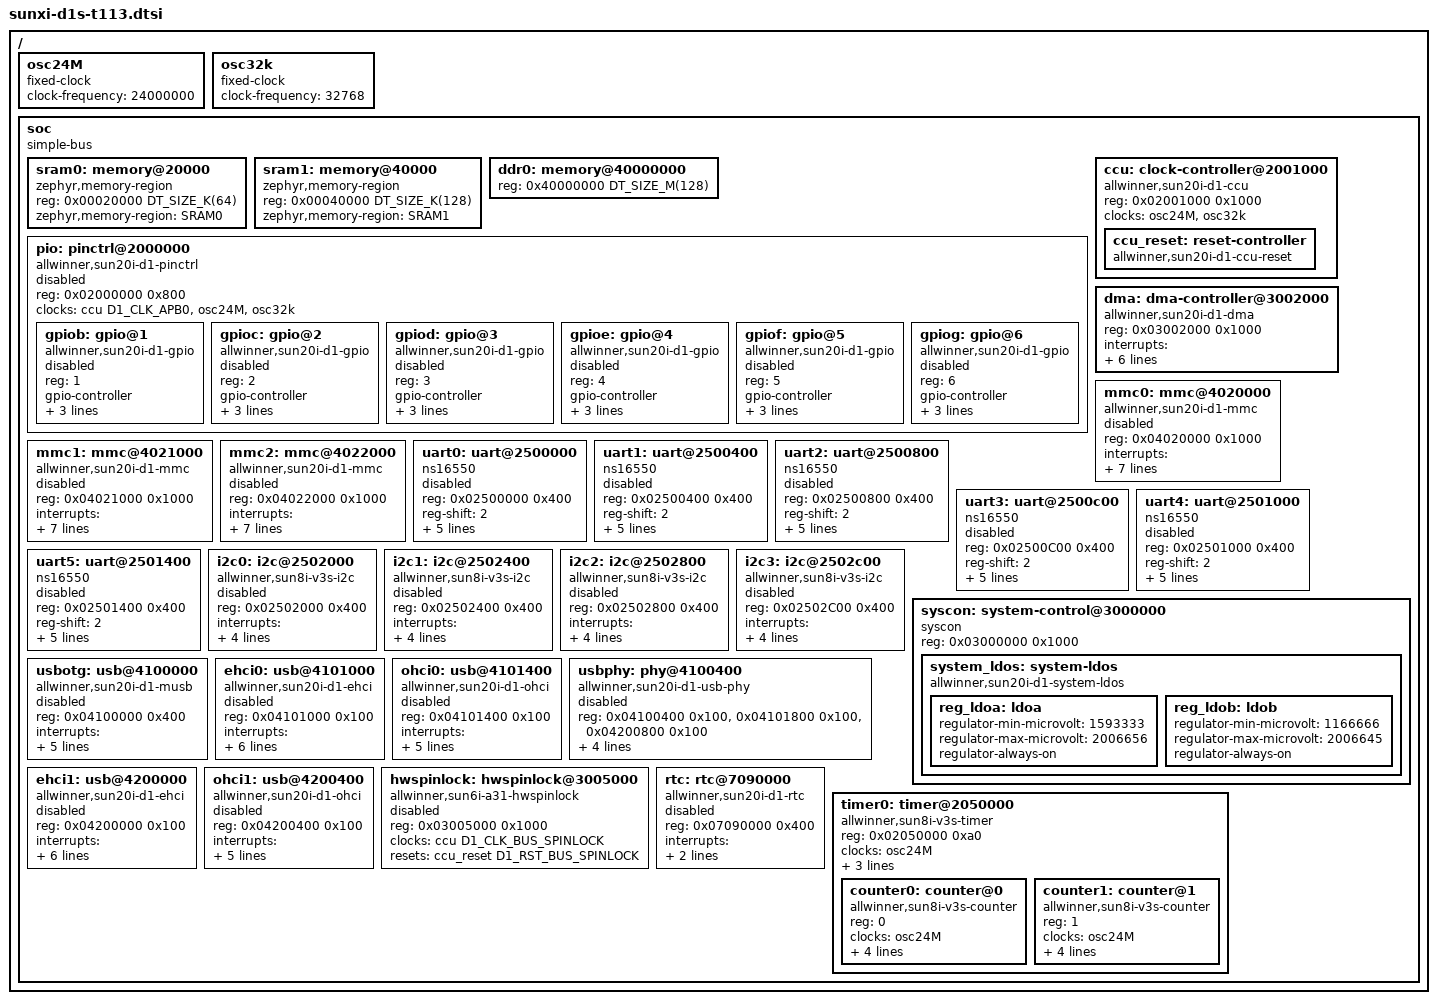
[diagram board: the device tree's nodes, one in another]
/*
 * Copyright (c) 2026 jeck chen <baidxi404629@gmail.com>
 * SPDX-License-Identifier: Apache-2.0
 *
 * Allwinner D1s / T113-S3 shared peripheral definitions.
 */

#include <mem.h>
#include <freq.h>
#include <zephyr/dt-bindings/interrupt-controller/arm-gic.h>
#include <zephyr/dt-bindings/clock/sun20i-d1-ccu.h>
#include <zephyr/dt-bindings/reset/sun20i-d1-ccu.h>
#include <zephyr/dt-bindings/dma/allwinner,sun20i-d1-dma.h>

/ {
	osc24M: osc24M {
		compatible = "fixed-clock";
		clock-frequency = <24000000>;
		#clock-cells = <0>;
	};

	osc32k: osc32k {
		compatible = "fixed-clock";
		clock-frequency = <32768>;
		#clock-cells = <0>;
	};

	soc {
		compatible = "simple-bus";
		#address-cells = <1>;
		#size-cells = <1>;
		ranges;

		sram0: memory@20000 {
			device_type = "memory";
			compatible = "zephyr,memory-region", "mmio-sram";
			reg = <0x00020000 DT_SIZE_K(64)>;
			zephyr,memory-region = "SRAM0";
		};

		sram1: memory@40000 {
			device_type = "memory";
			compatible = "zephyr,memory-region", "mmio-sram";
			reg = <0x00040000 DT_SIZE_K(128)>;
			zephyr,memory-region = "SRAM1";
		};

		ddr0: memory@40000000 {
			device_type = "memory";
			reg = <0x40000000 DT_SIZE_M(128)>;
		};

		pio: pinctrl@2000000 {
			compatible = "allwinner,sun20i-d1-pinctrl";
			reg = <0x02000000 0x800>;
			clocks = <&ccu D1_CLK_APB0>, <&osc24M>, <&osc32k>;
			clock-names = "apb", "hosc", "losc";
			#address-cells = <1>;
			#size-cells = <0>;
			status = "disabled";

			/*
			 * PLIC IRQ per bank (from Linux sunxi-d1s-t113.dtsi):
			 * PB=69, PC=71, PD=73, PE=75, PF=77, PG=79
			 */
			gpiob: gpio@1 {
				compatible = "allwinner,sun20i-d1-gpio";
				reg = <1>;
				gpio-controller;
				#gpio-cells = <2>;
				interrupt-parent = <&gic>;
				interrupts = <GIC_SPI 69 IRQ_TYPE_LEVEL IRQ_DEFAULT_PRIORITY>;
				status = "disabled";
			};
			gpioc: gpio@2 {
				compatible = "allwinner,sun20i-d1-gpio";
				reg = <2>;
				gpio-controller;
				#gpio-cells = <2>;
				interrupt-parent = <&gic>;
				interrupts = <GIC_SPI 71 IRQ_TYPE_LEVEL IRQ_DEFAULT_PRIORITY>;
				status = "disabled";
			};
			gpiod: gpio@3 {
				compatible = "allwinner,sun20i-d1-gpio";
				reg = <3>;
				gpio-controller;
				#gpio-cells = <2>;
				interrupt-parent = <&gic>;
				interrupts = <GIC_SPI 73 IRQ_TYPE_LEVEL IRQ_DEFAULT_PRIORITY>;
				status = "disabled";
			};
			gpioe: gpio@4 {
				compatible = "allwinner,sun20i-d1-gpio";
				reg = <4>;
				gpio-controller;
				#gpio-cells = <2>;
				interrupt-parent = <&gic>;
				interrupts = <GIC_SPI 75 IRQ_TYPE_LEVEL IRQ_DEFAULT_PRIORITY>;
				status = "disabled";
			};
			gpiof: gpio@5 {
				compatible = "allwinner,sun20i-d1-gpio";
				reg = <5>;
				gpio-controller;
				#gpio-cells = <2>;
				interrupt-parent = <&gic>;
				interrupts = <GIC_SPI 77 IRQ_TYPE_LEVEL IRQ_DEFAULT_PRIORITY>;
				status = "disabled";
			};
			gpiog: gpio@6 {
				compatible = "allwinner,sun20i-d1-gpio";
				reg = <6>;
				gpio-controller;
				#gpio-cells = <2>;
				interrupt-parent = <&gic>;
				interrupts = <GIC_SPI 79 IRQ_TYPE_LEVEL IRQ_DEFAULT_PRIORITY>;
				status = "disabled";
			};
		};

		ccu: clock-controller@2001000 {
			compatible = "allwinner,sun20i-d1-ccu";
			reg = <0x02001000 0x1000>;
			clocks = <&osc24M>, <&osc32k>;
			clock-names = "hosc", "losc";
			#clock-cells = <1>;
			#reset-cells = <1>;
			status = "okay";

			ccu_reset: reset-controller {
				compatible = "allwinner,sun20i-d1-ccu-reset";
				#reset-cells = <1>;
				status = "okay";
			};
		};

		dma: dma-controller@3002000 {
			compatible = "allwinner,sun20i-d1-dma";
			reg = <0x03002000 0x1000>;
			interrupts = <GIC_SPI 50 IRQ_TYPE_LEVEL IRQ_DEFAULT_PRIORITY>;
			clocks = <&ccu D1_CLK_BUS_DMA>, <&ccu D1_CLK_MBUS_DMA>;
			clock-names = "bus", "mbus";
			resets = <&ccu_reset D1_RST_BUS_DMA>;
			dma-channels = <16>;
			dma-requests = <48>;
			#dma-cells = <1>;
			status = "okay";
		};

		mmc0: mmc@4020000 {
			compatible = "allwinner,sun20i-d1-mmc";
			reg = <0x04020000 0x1000>;
			interrupts = <GIC_SPI 40 IRQ_TYPE_LEVEL IRQ_DEFAULT_PRIORITY>;
			clocks = <&ccu D1_CLK_BUS_MMC0>, <&ccu D1_CLK_MMC0>,
				 <&ccu D1_CLK_MMC0_OUTPUT>, <&ccu D1_CLK_MMC0_SAMPLE>;
			clock-names = "ahb", "mmc", "output", "sample";
			resets = <&ccu_reset D1_RST_BUS_MMC0>;
			reset-names = "ahb";
			bus-width = <4>;
			frequency = <DT_FREQ_M(24)>;
			status = "disabled";
			/* pinctrl provided by board overlay */
		};

		mmc1: mmc@4021000 {
			compatible = "allwinner,sun20i-d1-mmc";
			reg = <0x04021000 0x1000>;
			interrupts = <GIC_SPI 41 IRQ_TYPE_LEVEL IRQ_DEFAULT_PRIORITY>;
			clocks = <&ccu D1_CLK_BUS_MMC1>, <&ccu D1_CLK_MMC1>,
				 <&ccu D1_CLK_MMC1_OUTPUT>, <&ccu D1_CLK_MMC1_SAMPLE>;
			clock-names = "ahb", "mmc", "output", "sample";
			resets = <&ccu_reset D1_RST_BUS_MMC1>;
			reset-names = "ahb";
			bus-width = <4>;
			frequency = <DT_FREQ_M(24)>;
			status = "disabled";
			/* pinctrl provided by board overlay */
		};

		mmc2: mmc@4022000 {
			compatible = "allwinner,sun20i-d1-mmc";
			reg = <0x04022000 0x1000>;
			interrupts = <GIC_SPI 42 IRQ_TYPE_LEVEL IRQ_DEFAULT_PRIORITY>;
			clocks = <&ccu D1_CLK_BUS_MMC2>, <&ccu D1_CLK_MMC2>,
				 <&ccu D1_CLK_MMC2_OUTPUT>, <&ccu D1_CLK_MMC2_SAMPLE>;
			clock-names = "ahb", "mmc", "output", "sample";
			resets = <&ccu_reset D1_RST_BUS_MMC2>;
			reset-names = "ahb";
			bus-width = <8>;
			frequency = <DT_FREQ_M(24)>;
			status = "disabled";
			/* pinctrl provided by board overlay */
		};

		uart0: uart@2500000 {
			compatible = "ns16550", "snps,dw-apb-uart";
			reg = <0x02500000 0x400>;
			reg-shift = <2>;
			interrupts = <GIC_SPI 2 IRQ_TYPE_LEVEL IRQ_DEFAULT_PRIORITY>;
			clocks = <&ccu D1_CLK_BUS_UART0>;
			resets = <&ccu_reset D1_RST_BUS_UART0>;
			clock-frequency = <DT_FREQ_M(24)>;
			status = "disabled";
		};

		uart1: uart@2500400 {
			compatible = "ns16550", "snps,dw-apb-uart";
			reg = <0x02500400 0x400>;
			reg-shift = <2>;
			interrupts = <GIC_SPI 3 IRQ_TYPE_LEVEL IRQ_DEFAULT_PRIORITY>;
			clocks = <&ccu D1_CLK_BUS_UART1>;
			resets = <&ccu_reset D1_RST_BUS_UART1>;
			clock-frequency = <DT_FREQ_M(24)>;
			status = "disabled";
		};

		uart2: uart@2500800 {
			compatible = "ns16550", "snps,dw-apb-uart";
			reg = <0x02500800 0x400>;
			reg-shift = <2>;
			interrupts = <GIC_SPI 4 IRQ_TYPE_LEVEL IRQ_DEFAULT_PRIORITY>;
			clocks = <&ccu D1_CLK_BUS_UART2>;
			resets = <&ccu_reset D1_RST_BUS_UART2>;
			clock-frequency = <DT_FREQ_M(24)>;
			status = "disabled";
		};

		uart3: uart@2500c00 {
			compatible = "ns16550", "snps,dw-apb-uart";
			reg = <0x02500C00 0x400>;
			reg-shift = <2>;
			interrupts = <GIC_SPI 5 IRQ_TYPE_LEVEL IRQ_DEFAULT_PRIORITY>;
			clocks = <&ccu D1_CLK_BUS_UART3>;
			resets = <&ccu_reset D1_RST_BUS_UART3>;
			clock-frequency = <DT_FREQ_M(24)>;
			status = "disabled";
		};

		uart4: uart@2501000 {
			compatible = "ns16550", "snps,dw-apb-uart";
			reg = <0x02501000 0x400>;
			reg-shift = <2>;
			interrupts = <GIC_SPI 6 IRQ_TYPE_LEVEL IRQ_DEFAULT_PRIORITY>;
			clocks = <&ccu D1_CLK_BUS_UART4>;
			resets = <&ccu_reset D1_RST_BUS_UART4>;
			clock-frequency = <DT_FREQ_M(24)>;
			status = "disabled";
		};

		uart5: uart@2501400 {
			compatible = "ns16550", "snps,dw-apb-uart";
			reg = <0x02501400 0x400>;
			reg-shift = <2>;
			interrupts = <GIC_SPI 7 IRQ_TYPE_LEVEL IRQ_DEFAULT_PRIORITY>;
			clocks = <&ccu D1_CLK_BUS_UART5>;
			resets = <&ccu_reset D1_RST_BUS_UART5>;
			clock-frequency = <DT_FREQ_M(24)>;
			status = "disabled";
		};

		i2c0: i2c@2502000 {
			compatible = "allwinner,sun8i-v3s-i2c",
				     "allwinner,sun20i-d1-i2c";
			reg = <0x02502000 0x400>;
			interrupts = <GIC_SPI 9 IRQ_TYPE_LEVEL IRQ_DEFAULT_PRIORITY>;
			clocks = <&ccu D1_CLK_BUS_I2C0>;
			clock-names = "bus";
			resets = <&ccu_reset D1_RST_BUS_I2C0>;
			clock-frequency = <100000>;
			#address-cells = <1>;
			#size-cells = <0>;
			status = "disabled";
		};

		i2c1: i2c@2502400 {
			compatible = "allwinner,sun8i-v3s-i2c",
				     "allwinner,sun20i-d1-i2c";
			reg = <0x02502400 0x400>;
			interrupts = <GIC_SPI 10 IRQ_TYPE_LEVEL IRQ_DEFAULT_PRIORITY>;
			clocks = <&ccu D1_CLK_BUS_I2C1>;
			clock-names = "bus";
			resets = <&ccu_reset D1_RST_BUS_I2C1>;
			clock-frequency = <100000>;
			#address-cells = <1>;
			#size-cells = <0>;
			status = "disabled";
		};

		i2c2: i2c@2502800 {
			compatible = "allwinner,sun8i-v3s-i2c",
				     "allwinner,sun20i-d1-i2c";
			reg = <0x02502800 0x400>;
			interrupts = <GIC_SPI 11 IRQ_TYPE_LEVEL IRQ_DEFAULT_PRIORITY>;
			clocks = <&ccu D1_CLK_BUS_I2C2>;
			clock-names = "bus";
			resets = <&ccu_reset D1_RST_BUS_I2C2>;
			clock-frequency = <100000>;
			#address-cells = <1>;
			#size-cells = <0>;
			status = "disabled";
		};

		i2c3: i2c@2502c00 {
			compatible = "allwinner,sun8i-v3s-i2c",
				     "allwinner,sun20i-d1-i2c";
			reg = <0x02502C00 0x400>;
			interrupts = <GIC_SPI 12 IRQ_TYPE_LEVEL IRQ_DEFAULT_PRIORITY>;
			clocks = <&ccu D1_CLK_BUS_I2C3>;
			clock-names = "bus";
			resets = <&ccu_reset D1_RST_BUS_I2C3>;
			clock-frequency = <100000>;
			#address-cells = <1>;
			#size-cells = <0>;
			status = "disabled";
		};

		/* System Configuration (SYS_CFG) — base 0x03000000.
		 * Contains EMAC EPHY clock register (0x30), system LDOs
		 * (0x150), and DSP SRAM remap (0x08).
		 */
		syscon: system-control@3000000 {
			compatible = "syscon";
			reg = <0x03000000 0x1000>;
			status = "okay";

			system_ldos: system-ldos {
				compatible = "allwinner,sun20i-d1-system-ldos";
				status = "okay";

				reg_ldoa: ldoa {
					/* 1.593V – 2.007V, 32 steps (13.33mV/step) */
					regulator-min-microvolt = <1593333>;
					regulator-max-microvolt = <2006656>;
					regulator-always-on;
				};

				reg_ldob: ldob {
					/* 1.167V – 2.007V, 64 steps (13.33mV/step) */
					regulator-min-microvolt = <1166666>;
					regulator-max-microvolt = <2006645>;
					regulator-always-on;
				};
			};
		};

		usbotg: usb@4100000 {
			compatible = "allwinner,sun20i-d1-musb",
				     "allwinner,sun8i-v3s-musb";
			reg = <0x04100000 0x400>;
			interrupts = <GIC_SPI 29 IRQ_TYPE_LEVEL IRQ_DEFAULT_PRIORITY>;
			clocks = <&ccu D1_CLK_BUS_OTG>;
			resets = <&ccu_reset D1_RST_BUS_OTG>;
			phys = <&usbphy 0>;
			phy-names = "usb";
			num-bidir-endpoints = <6>;
			status = "disabled";
		};

		ehci0: usb@4101000 {
			compatible = "allwinner,sun20i-d1-ehci", "generic-ehci";
			reg = <0x04101000 0x100>;
			interrupts = <GIC_SPI 30 IRQ_TYPE_LEVEL IRQ_DEFAULT_PRIORITY>;
			clocks = <&ccu D1_CLK_BUS_OHCI0>,
				 <&ccu D1_CLK_BUS_EHCI0>,
				 <&ccu D1_CLK_USB_OHCI0>;
			resets = <&ccu_reset D1_RST_BUS_OHCI0>,
				 <&ccu_reset D1_RST_BUS_EHCI0>;
			phys = <&usbphy 0>;
			phy-names = "usb";
			status = "disabled";
		};

		ohci0: usb@4101400 {
			compatible = "allwinner,sun20i-d1-ohci", "generic-ohci";
			reg = <0x04101400 0x100>;
			interrupts = <GIC_SPI 31 IRQ_TYPE_LEVEL IRQ_DEFAULT_PRIORITY>;
			clocks = <&ccu D1_CLK_BUS_OHCI0>,
				 <&ccu D1_CLK_USB_OHCI0>;
			resets = <&ccu_reset D1_RST_BUS_OHCI0>;
			phys = <&usbphy 0>;
			phy-names = "usb";
			status = "disabled";
		};

		usbphy: phy@4100400 {
			compatible = "allwinner,sun20i-d1-usb-phy",
				     "allwinner,sun4i-usb-phy";
			reg = <0x04100400 0x100>,
			      <0x04101800 0x100>,
			      <0x04200800 0x100>;
			reg-names = "phy_ctrl", "pmu0", "pmu1";
			clocks = <&osc24M>,
				 <&osc24M>;
			clock-names = "usb0_phy", "usb1_phy";
			resets = <&ccu_reset D1_RST_USB_PHY0>,
				 <&ccu_reset D1_RST_USB_PHY1>;
			reset-names = "usb0_reset", "usb1_reset";
			#phy-cells = <1>;
			phy0-dual-route;
			status = "disabled";
		};

		ehci1: usb@4200000 {
			compatible = "allwinner,sun20i-d1-ehci", "generic-ehci";
			reg = <0x04200000 0x100>;
			interrupts = <GIC_SPI 33 IRQ_TYPE_LEVEL IRQ_DEFAULT_PRIORITY>;
			clocks = <&ccu D1_CLK_BUS_OHCI1>,
				 <&ccu D1_CLK_BUS_EHCI1>,
				 <&ccu D1_CLK_USB_OHCI1>;
			resets = <&ccu_reset D1_RST_BUS_OHCI1>,
				 <&ccu_reset D1_RST_BUS_EHCI1>;
			phys = <&usbphy 1>;
			phy-names = "usb";
			status = "disabled";
		};

		ohci1: usb@4200400 {
			compatible = "allwinner,sun20i-d1-ohci", "generic-ohci";
			reg = <0x04200400 0x100>;
			interrupts = <GIC_SPI 34 IRQ_TYPE_LEVEL IRQ_DEFAULT_PRIORITY>;
			clocks = <&ccu D1_CLK_BUS_OHCI1>,
				 <&ccu D1_CLK_USB_OHCI1>;
			resets = <&ccu_reset D1_RST_BUS_OHCI1>;
			phys = <&usbphy 1>;
			phy-names = "usb";
			status = "disabled";
		};

		hwspinlock: hwspinlock@3005000 {
			compatible = "allwinner,sun6i-a31-hwspinlock";
			reg = <0x03005000 0x1000>;
			clocks = <&ccu D1_CLK_BUS_SPINLOCK>;
			resets = <&ccu_reset D1_RST_BUS_SPINLOCK>;
			#hwlock-cells = <1>;
			status = "disabled";
		};

		rtc: rtc@7090000 {
			compatible = "allwinner,sun20i-d1-rtc";
			reg = <0x07090000 0x400>;
			interrupts = <GIC_SPI 144 IRQ_TYPE_LEVEL IRQ_DEFAULT_PRIORITY>;
			alarms-count = <1>;
			status = "disabled";
		};

		timer0: timer@2050000 {
			compatible = "allwinner,sun8i-v3s-timer";
			reg = <0x02050000 0xa0>;
			clocks = <&osc24M>;
			interrupts = <GIC_SPI 59 IRQ_TYPE_LEVEL IRQ_DEFAULT_PRIORITY>,
				     <GIC_SPI 60 IRQ_TYPE_LEVEL IRQ_DEFAULT_PRIORITY>;
			#address-cells = <1>;
			#size-cells = <0>;
			status = "okay";

			counter0: counter@0 {
				compatible = "allwinner,sun8i-v3s-counter";
				reg = <0>;
				clocks = <&osc24M>;
				interrupts = <GIC_SPI 59 IRQ_TYPE_LEVEL IRQ_DEFAULT_PRIORITY>;
				clock-source = <1>;
				prescaler = <0>;
				status = "okay";
			};

			counter1: counter@1 {
				compatible = "allwinner,sun8i-v3s-counter";
				reg = <1>;
				clocks = <&osc24M>;
				interrupts = <GIC_SPI 60 IRQ_TYPE_LEVEL IRQ_DEFAULT_PRIORITY>;
				clock-source = <1>;
				prescaler = <0>;
				status = "okay";
			};
		};
	};
};
